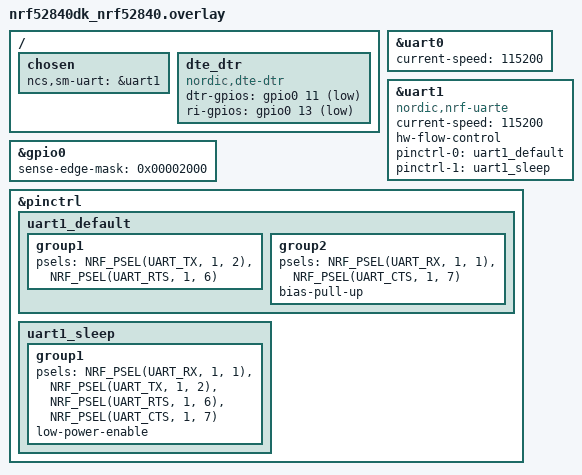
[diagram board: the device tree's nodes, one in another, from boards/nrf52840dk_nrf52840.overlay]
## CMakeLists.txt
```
#
# Copyright (c) 2023 Nordic Semiconductor ASA
#
# SPDX-License-Identifier: LicenseRef-Nordic-5-Clause
#

cmake_minimum_required(VERSION 3.20.0)

find_package(Zephyr REQUIRED HINTS $ENV{ZEPHYR_BASE})
project(sm_host_shell)

target_sources(app PRIVATE src/main.c)
```

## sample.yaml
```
sample:
  description: Serial Modem Shell sample
  name: SM shell
tests:
  sample.cellular.sm_host_shell:
    sysbuild: true
    build_only: true
    platform_allow:
      - nrf54l15dk/nrf54l15/cpuapp
      - nrf52840dk/nrf52840
      - nrf5340dk/nrf5340/cpuapp
      - nrf7002dk/nrf5340/cpuapp
    integration_platforms:
      - nrf54l15dk/nrf54l15/cpuapp
      - nrf5340dk/nrf5340/cpuapp
```

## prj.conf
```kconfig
#
# Copyright (c) 2023 Nordic Semiconductor ASA
#
# SPDX-License-Identifier: LicenseRef-Nordic-5-Clause
#

CONFIG_STACK_SENTINEL=y
CONFIG_MAIN_STACK_SIZE=4096
CONFIG_HEAP_MEM_POOL_SIZE=8192
CONFIG_SYSTEM_WORKQUEUE_STACK_SIZE=2048

CONFIG_LOG=y
CONFIG_LOG_BACKEND_UART=y
CONFIG_CONSOLE=y
CONFIG_UART_CONSOLE=y
CONFIG_SHELL=y
CONFIG_SHELL_WILDCARD=n
CONFIG_SHELL_ARGC_MAX=40
CONFIG_SHELL_CMD_BUFF_SIZE=1024
CONFIG_SHELL_STACK_SIZE=2048
CONFIG_SHELL_LOG_BACKEND=n

CONFIG_SERIAL=y
CONFIG_UART_ASYNC_API=y

CONFIG_SM_HOST=y
CONFIG_SM_HOST_SHELL=y
CONFIG_SM_HOST_LOG_LEVEL_INF=y

CONFIG_ASSERT=y
```

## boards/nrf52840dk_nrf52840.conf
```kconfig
#
# Copyright (c) 2023 Nordic Semiconductor ASA
#
# SPDX-License-Identifier: LicenseRef-Nordic-5-Clause
#

# Configuration file for nRF52840DK.
# This file is merged with prj.conf in the application folder, and options
# set here will take precedence if they are present in both files.

CONFIG_NRFX_UARTE1=y
CONFIG_UART_1_INTERRUPT_DRIVEN=n
CONFIG_UART_1_ASYNC=y
```

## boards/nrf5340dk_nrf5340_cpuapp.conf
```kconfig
#
# Copyright (c) 2023 Nordic Semiconductor ASA
#
# SPDX-License-Identifier: LicenseRef-Nordic-5-Clause
#

# Configuration file for nRF5340DK.
# This file is merged with prj.conf in the application folder, and options
# set here will take precedence if they are present in both files.

CONFIG_NRFX_UARTE2=y
CONFIG_UART_2_INTERRUPT_DRIVEN=n
CONFIG_UART_2_ASYNC=y
CONFIG_SM_HOST_POWER_PIN=23
CONFIG_SM_HOST_INDICATE_PIN=28
```

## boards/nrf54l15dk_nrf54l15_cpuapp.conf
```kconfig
#
# Copyright (c) 2025 Nordic Semiconductor ASA
#
# SPDX-License-Identifier: LicenseRef-Nordic-5-Clause
#

# Configuration file for nRF54L15DK.
# This file is merged with prj.conf in the application folder, and options
# set here will take precedence if they are present in both files.

CONFIG_NRFX_UARTE30=y
CONFIG_UART_30_INTERRUPT_DRIVEN=n
CONFIG_UART_30_ASYNC=y
```

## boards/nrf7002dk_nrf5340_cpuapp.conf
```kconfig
#
# Copyright (c) 2023 Nordic Semiconductor ASA
#
# SPDX-License-Identifier: LicenseRef-Nordic-5-Clause
#

# Configuration file for nRF7002DK.
# This file is merged with prj.conf in the application folder, and options
# set here will take precedence if they are present in both files.

CONFIG_NRFX_UARTE2=y
CONFIG_UART_2_INTERRUPT_DRIVEN=n
CONFIG_UART_2_ASYNC=y
CONFIG_SM_HOST_POWER_PIN=30
CONFIG_SM_HOST_INDICATE_PIN=31
```

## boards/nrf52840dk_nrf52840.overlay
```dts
/*
 * Copyright (c) 2023 Nordic Semiconductor ASA
 *
 * SPDX-License-Identifier: LicenseRef-Nordic-5-Clause
 */

/ {
	chosen {
		ncs,sm-uart = &uart1;
	};
};

/* Shell UART */
&uart0 {
	current-speed = <115200>;
	status = "okay";
};

/* Serial Modem Host Shell <-> Serial Modem UART */
&uart1 {
	compatible = "nordic,nrf-uarte";
	current-speed = <115200>;
	status = "okay";
	hw-flow-control;

	pinctrl-0 = <&uart1_default>;
	pinctrl-1 = <&uart1_sleep>;
	pinctrl-names = "default", "sleep";
};

/* DTR gpios for uart1 */
/ {
	dte_dtr: dte_dtr {
		compatible = "nordic,dte-dtr";
		dtr-gpios = <&gpio0 11 GPIO_ACTIVE_LOW>;
		ri-gpios = <&gpio0 13 (GPIO_ACTIVE_LOW | GPIO_PULL_UP)>;
	};
};

&gpio0 {
	status = "okay";
	/* Use PORT event for RI (13) pin to ensure lower power consumption. */
	sense-edge-mask = <0x00002000>;
};


&pinctrl {
	uart1_default: uart1_default {
		group1 {
			psels = <NRF_PSEL(UART_TX, 1, 2)>,
				<NRF_PSEL(UART_RTS, 1, 6)>;
		};
		group2 {
			psels = <NRF_PSEL(UART_RX, 1, 1)>,
				<NRF_PSEL(UART_CTS, 1, 7)>;
			bias-pull-up;
		};
	};

	uart1_sleep: uart1_sleep {
		group1 {
			psels = <NRF_PSEL(UART_RX, 1, 1)>,
				<NRF_PSEL(UART_TX, 1, 2)>,
				<NRF_PSEL(UART_RTS, 1, 6)>,
				<NRF_PSEL(UART_CTS, 1, 7)>;
			low-power-enable;
		};
	};
};
```

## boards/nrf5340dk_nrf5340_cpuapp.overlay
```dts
/*
 * Copyright (c) 2023 Nordic Semiconductor ASA
 *
 * SPDX-License-Identifier: LicenseRef-Nordic-5-Clause
 */

/ {
	chosen {
		ncs,sm-uart = &uart2;
	};
};

/* Shell UART */
&uart0 {
	current-speed = <115200>;
	status = "okay";
};

/* Serial Modem Host Shell <-> Serial Modem UART */
&uart2 {
	compatible = "nordic,nrf-uarte";
	current-speed = <115200>;
	status = "okay";
	hw-flow-control;
	pinctrl-0 = <&uart2_default>;
	pinctrl-1 = <&uart2_sleep>;
	pinctrl-names = "default", "sleep";
};

/* DTR gpios for uart2 */
/ {
	dte_dtr: dte_dtr {
		compatible = "nordic,dte-dtr";
		dtr-gpios = <&gpio0 23 GPIO_ACTIVE_LOW>;
		ri-gpios = <&gpio0 28 (GPIO_ACTIVE_LOW | GPIO_PULL_UP)>;
	};
};

&gpio0 {
	status = "okay";
	/* Use PORT event for RI (28) pin to ensure lower power consumption. */
	sense-edge-mask = <0x10000000>;
};


&pinctrl {
	uart2_default: uart2_default {
		group1 {
			psels = <NRF_PSEL(UART_TX, 1, 4)>,
				<NRF_PSEL(UART_RTS, 1, 6)>;
		};
		group2 {
			psels = <NRF_PSEL(UART_RX, 1, 5)>,
				<NRF_PSEL(UART_CTS, 1, 7)>;
			bias-pull-up;
		};
	};

	uart2_sleep: uart2_sleep {
		group1 {
			psels = <NRF_PSEL(UART_TX, 1, 4)>,
				<NRF_PSEL(UART_RX, 1, 5)>,
				<NRF_PSEL(UART_RTS, 1, 6)>,
				<NRF_PSEL(UART_CTS, 1, 7)>;
			low-power-enable;
		};
	};
};
```

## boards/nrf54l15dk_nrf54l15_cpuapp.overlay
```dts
/*
 * Copyright (c) 2025 Nordic Semiconductor ASA
 *
 * SPDX-License-Identifier: LicenseRef-Nordic-5-Clause
 */

/ {
	chosen {
		ncs,sm-uart = &uart30;
	};
};

/* Shell UART */
&uart20 {
	current-speed = <115200>;
	status = "okay";
};

/* Serial Modem Host Shell <-> Serial Modem UART */
/* Note: Disable VCOM0 from Board Configurator to release UART30 for SM. */
&uart30 {
	compatible = "nordic,nrf-uarte";
	current-speed = <115200>;
	status = "okay";
	hw-flow-control;
};

/* DTR gpios for uart30 */
/ {
	dte_dtr: dte_dtr {
		compatible = "nordic,dte-dtr";
		dtr-gpios = <&gpio1 11 GPIO_ACTIVE_LOW>;
		ri-gpios = <&gpio1 12 (GPIO_ACTIVE_LOW | GPIO_PULL_UP)>;
	};
};
```

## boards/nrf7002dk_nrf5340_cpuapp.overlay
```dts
/*
 * Copyright (c) 2023 Nordic Semiconductor ASA
 *
 * SPDX-License-Identifier: LicenseRef-Nordic-5-Clause
 */

/ {
	chosen {
		ncs,sm-uart = &uart2;
	};
};

/* Shell UART */
&uart0 {
	current-speed = <115200>;
	status = "okay";
};

/* Serial Modem Host Shell <-> Serial Modem UART */
&uart2 {
	compatible = "nordic,nrf-uarte";
	current-speed = <115200>;
	status = "okay";
	hw-flow-control;

	pinctrl-0 = <&uart2_default>;
	pinctrl-1 = <&uart2_sleep>;
	pinctrl-names = "default", "sleep";
};

/* DTR gpios for uart2 */
/ {
	dte_dtr: dte_dtr {
		compatible = "nordic,dte-dtr";
		dtr-gpios = <&gpio0 30 GPIO_ACTIVE_LOW>;
		ri-gpios = <&gpio0 31 (GPIO_ACTIVE_LOW | GPIO_PULL_UP)>;
	};
};

&gpio0 {
	status = "okay";
	/* Use PORT event for RI (31) pin to ensure lower power consumption. */
	sense-edge-mask = <0x80000000>;
};

&pinctrl {
	uart2_default: uart2_default {
		group1 {
			psels = <NRF_PSEL(UART_TX, 1, 4)>,
				<NRF_PSEL(UART_RTS, 1, 6)>;

		};
		group2 {
			psels = <NRF_PSEL(UART_RX, 1, 5)>,
				<NRF_PSEL(UART_CTS, 1, 7)>;
			bias-pull-up;
		};
	};

	uart2_sleep: uart2_sleep {
		group1 {
			psels = <NRF_PSEL(UART_TX, 1, 4)>,
				<NRF_PSEL(UART_RX, 1, 5)>,
				<NRF_PSEL(UART_RTS, 1, 6)>,
				<NRF_PSEL(UART_CTS, 1, 7)>;
			low-power-enable;
		};
	};
};
```

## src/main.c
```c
/*
 * Copyright (c) 2023 Nordic Semiconductor ASA
 *
 * SPDX-License-Identifier: LicenseRef-Nordic-5-Clause
 */

#include <stdlib.h>
#include <sm_host.h>
#include <zephyr/logging/log.h>

LOG_MODULE_REGISTER(app, CONFIG_LOG_DEFAULT_LEVEL);

SM_MONITOR(network, "\r\n+CEREG:", cereg_mon);

static void cereg_mon(const char *notif)
{
	int status = atoi(notif + strlen("\r\n+CEREG: "));

	if (status == 1 || status == 5) {
		LOG_INF("LTE connected");
	}
}

void sm_host_shell_data_indication(const uint8_t *data, size_t datalen)
{
	ARG_UNUSED(data);
	ARG_UNUSED(datalen);

	/* Add data handler implementation in here. */
}

void sm_host_shell_ri_handler(void)
{
	LOG_INF("Ring Indicate (RI) triggered");
}

int main(void)
{
	int err;

	LOG_INF("Serial Modem Host Shell starts on %s", CONFIG_BOARD);

	err = sm_host_init(sm_host_shell_data_indication, true, K_MSEC(100));
	if (err) {
		LOG_ERR("Failed to initialize Serial Modem: %d", err);
	}

	err = sm_host_register_ri_handler(sm_host_shell_ri_handler);
	if (err) {
		LOG_ERR("Failed to register RI handler (%d).", err);
	}

	return 0;
}
```
